# STM32L562xx register map
File version: 1.0
Registers are 32-bit, read-write, reset 0x0 unless marked. A register's access mark holds for its fields unless they carry their own. Offsets are from the block's base; [hi:lo] are bit positions; {n}, {i} and the like mark numbered series.

## AES — AES hardware accelerator
Base 0x420C0000
Same registers: AES_S 0x520C0000
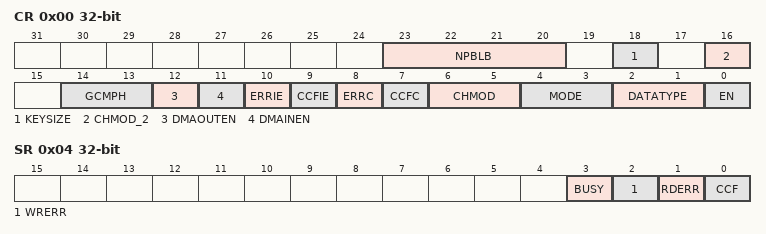
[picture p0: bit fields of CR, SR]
0x00 CR — AES control register
  [23:20] NPBLB — Number of padding bytes in payload last block
  [18] KEYSIZE — Key size selection
  [16] CHMOD_2 — AES Chaining Mode
  [14:13] GCMPH — GCM Phase
  [12] DMAOUTEN — Enable data output phase DMA management
  [11] DMAINEN — Enable data input phase DMA management
  [10] ERRIE — Error Interrupt Enable
  [9] CCFIE — Computation Complete Flag Interrupt Enable
  [8] ERRC — Error Clear
  [7] CCFC — Computation Complete Flag Clear
  [6:5] CHMOD — AES Chaining Mode
  [4:3] MODE — AES Mode Of Operation
  [2:1] DATATYPE — Data type selection
  [0] EN — AES Enable
0x04 SR — AES status register
  [3] BUSY — Busy Flag
  [2] WRERR — Write Error Flag
  [1] RDERR — Read Error Flag
  [0] CCF — Computation Complete Flag
0x08 DINR — AES data input register
  [31:0] DINR — AES Data Input Register
0x0C DOUTR — AES data output register
  [31:0] DOUTR — AES Data Output Register
{0x10+4i} KEYR{i} (i=0..3) — AES key register {i}
  [31:0] KEYR{i} — AES Key Register {i}
{0x20+4i} IVR{i} (i=0..3) — AES initialization vector register {i}
  [31:0] IVR{i} — AES Initialization Vector Register {i}
{0x20+4i} KEYR{i} (i=4..7) — AES key register {i}
  [31:0] KEYR{i} — AES Key Register {i}
{0x40+4i} SUSP{i}R (i=0..7) — AES Suspend register {i}
  [31:0] SUSP{i}R — AES Suspend registers {i}

## HASH
Base 0x420C0400
Same registers: HASH_S 0x520C0400
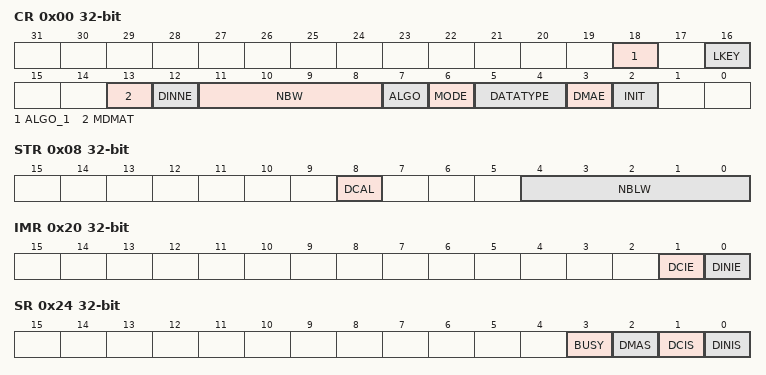
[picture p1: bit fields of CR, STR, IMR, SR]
0x00 CR — HASH control register
  [18] ALGO_1, [16] LKEY, [13] MDMAT, [12] DINNE, [11:8] NBW, [7] ALGO, [6] MODE, [5:4] DATATYPE, [3] DMAE, [2] INIT
0x04 DIN — HASH data input register
0x08 STR — HASH start register
  [8] DCAL, [4:0] NBLW
{0xC+4i} HR{i} (i=0..4) — HASH digest registers
0x20 IMR — HASH interrupt enable register
  [1] DCIE, [0] DINIE
0x24 SR — HASH status register
  [3] BUSY, [2] DMAS, [1] DCIS, [0] DINIS
{0xF8+4i} CSR{i} (i=0..53) — HASH context swap registers
{0x310+4i} DIGEST_HR{i} (i=0..7) — HASH digest registers

## RNG
Base 0x420C0800
Same registers: RNG_S 0x520C0800
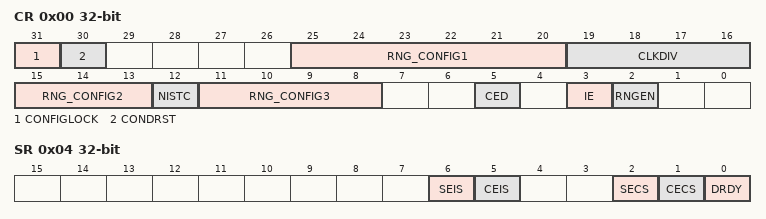
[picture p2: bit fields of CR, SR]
0x00 CR — RNG control register
  [31] CONFIGLOCK
  [30] CONDRST
  [25:20] RNG_CONFIG1
  [19:16] CLKDIV
    0=BY_1 (No clock division); 1=BY_2 (2 RNG clock cycles per internal RNG clock); 2=BY_4 (4 RNG clock cycles per internal RNG clock); 3=BY_8 (8 RNG clock cycles per internal RNG clock); 4=BY_16 (16 RNG clock cycles per internal RNG clock); 5=BY_32 (32 RNG clock cycles per internal RNG clock); 6=BY_64 (64 RNG clock cycles per internal RNG clock); 7=BY_128 (128 RNG clock cycles per internal RNG clock); 8=BY_256 (256 RNG clock cycles per internal RNG clock); 9=BY_512 (512 RNG clock cycles per internal RNG clock); 10=BY_1024 (1024 RNG clock cycles per internal RNG clock); 11=BY_2048 (2048 RNG clock cycles per internal RNG clock); 12=BY_4096 (4096 RNG clock cycles per internal RNG clock); 13=BY_8192 (8192 RNG clock cycles per internal RNG clock); 14=BY_16384 (16384 RNG clock cycles per internal RNG clock); 15=BY_32768 (32768 RNG clock cycles per internal RNG clock)
  [15:13] RNG_CONFIG2
  [12] NISTC
  [11:8] RNG_CONFIG3
  [5] CED
  [3] IE
  [2] RNGEN
0x04 SR — RNG status register
  [6] SEIS, [5] CEIS, [2] SECS, [1] CECS, [0] DRDY
0x08 DR — RNG data register
  [31:0] RNDATA
0x10 HTCR — RNG health test control register
  [31:0] HTCFG

## PKA — Public Key Accelerator (PKA)
Base 0x420C2000
Same registers: PKA_S 0x520C2000
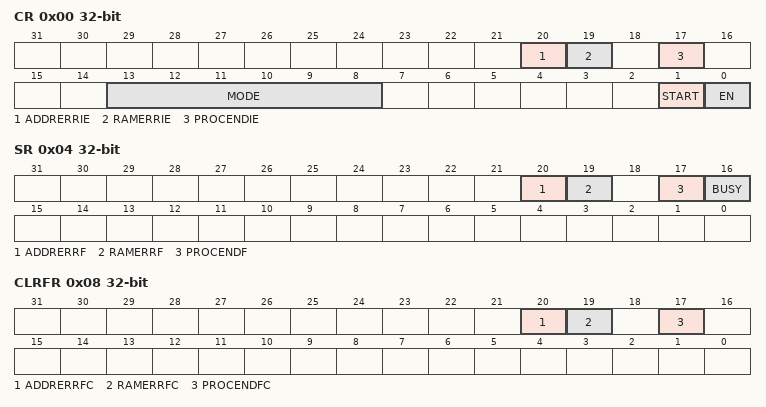
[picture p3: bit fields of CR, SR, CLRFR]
0x00 CR — PKA control register
  [20] ADDRERRIE — RAM error interrupt enable
  [19] RAMERRIE — RAM error interrupt enable
  [17] PROCENDIE — End of operation interrupt enable
  [13:8] MODE — MODE[5:0] PKA operation code
  [1] START — Start operation
  [0] EN — PKA enable
0x04 SR — PKA status register
  [20] ADDRERRF — Address error flag
  [19] RAMERRF — PKA RAM error flag
  [17] PROCENDF — PKA end of operation flag
  [16] BUSY — PKA operation is in progress
0x08 CLRFR — PKA clear flag register
  [20] ADDRERRFC — Clear address error flag
  [19] RAMERRFC — Clear PKA RAM error flag
  [17] PROCENDFC — Clear PKA end of operation flag
{0x400+4i} RAM[{i}] (i=0..893)
